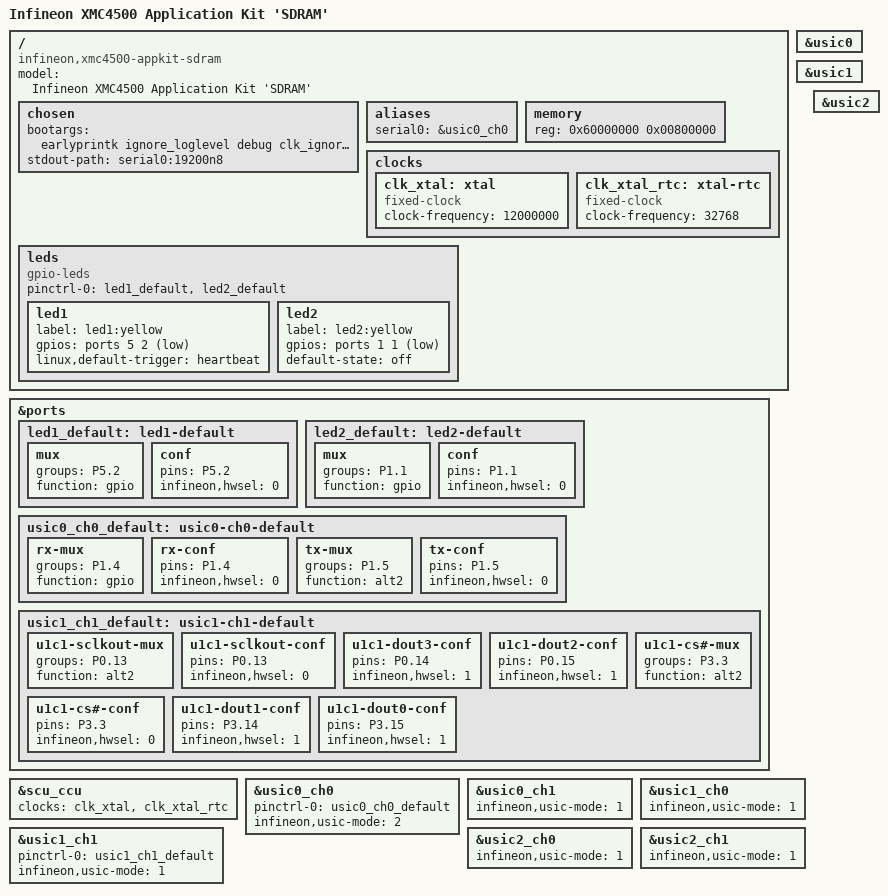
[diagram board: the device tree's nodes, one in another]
/*
 * Copyright 2015-2016 Andreas Färber
 *
 * This file is dual-licensed: you can use it either under the terms
 * of the GPL or the X11 license, at your option. Note that this dual
 * licensing only applies to this file, and not this project as a
 * whole.
 *
 *  a) This file is free software; you can redistribute it and/or
 *     modify it under the terms of the GNU General Public License as
 *     published by the Free Software Foundation; either version 2 of the
 *     License, or (at your option) any later version.
 *
 *     This file is distributed in the hope that it will be useful,
 *     but WITHOUT ANY WARRANTY; without even the implied warranty of
 *     MERCHANTABILITY or FITNESS FOR A PARTICULAR PURPOSE.  See the
 *     GNU General Public License for more details.
 *
 * Or, alternatively,
 *
 *  b) Permission is hereby granted, free of charge, to any person
 *     obtaining a copy of this software and associated documentation
 *     files (the "Software"), to deal in the Software without
 *     restriction, including without limitation the rights to use,
 *     copy, modify, merge, publish, distribute, sublicense, and/or
 *     sell copies of the Software, and to permit persons to whom the
 *     Software is furnished to do so, subject to the following
 *     conditions:
 *
 *     The above copyright notice and this permission notice shall be
 *     included in all copies or substantial portions of the Software.
 *
 *     THE SOFTWARE IS PROVIDED "AS IS", WITHOUT WARRANTY OF ANY KIND,
 *     EXPRESS OR IMPLIED, INCLUDING BUT NOT LIMITED TO THE WARRANTIES
 *     OF MERCHANTABILITY, FITNESS FOR A PARTICULAR PURPOSE AND
 *     NONINFRINGEMENT. IN NO EVENT SHALL THE AUTHORS OR COPYRIGHT
 *     HOLDERS BE LIABLE FOR ANY CLAIM, DAMAGES OR OTHER LIABILITY,
 *     WHETHER IN AN ACTION OF CONTRACT, TORT OR OTHERWISE, ARISING
 *     FROM, OUT OF OR IN CONNECTION WITH THE SOFTWARE OR THE USE OR
 *     OTHER DEALINGS IN THE SOFTWARE.
 */

/dts-v1/;

#include "xmc4500.dtsi"
#include <dt-bindings/gpio/gpio.h>

/ {
	model = "Infineon XMC4500 Application Kit 'SDRAM'";
	compatible = "infineon,xmc4500-appkit-sdram", "infineon,xmc4500";

	chosen {
		bootargs = "earlyprintk ignore_loglevel debug clk_ignore_unused";
		stdout-path = "serial0:19200n8";
	};

	aliases {
		serial0 = &usic0_ch0;
	};

	memory {
		reg = <0x60000000 0x00800000>;
	};

	clocks {
		clk_xtal: xtal {
			compatible = "fixed-clock";
			clock-frequency = <12000000>;
			#clock-cells = <0>;
		};

		clk_xtal_rtc: xtal-rtc {
			compatible = "fixed-clock";
			clock-frequency = <32768>;
			#clock-cells = <0>;
		};
	};

	leds {
		compatible = "gpio-leds";
		pinctrl-names = "default";
		pinctrl-0 = <&led1_default>, <&led2_default>;

		led1 {
			label = "led1:yellow";
			gpios = <&ports 5 2 GPIO_ACTIVE_LOW>;
			linux,default-trigger = "heartbeat";
		};

		led2 {
			label = "led2:yellow";
			gpios = <&ports 1 1 GPIO_ACTIVE_LOW>;
			/*linux,default-trigger = "heartbeat";*/
			default-state = "off";
		};
	};
};

&ports {
	led1_default: led1-default {
		mux {
			groups = "P5.2";
			function = "gpio";
		};

		conf {
			pins = "P5.2";
			infineon,hwsel = <0>;
		};
	};

	led2_default: led2-default {
		mux {
			groups = "P1.1";
			function = "gpio";
		};

		conf {
			pins = "P1.1";
			infineon,hwsel = <0>;
		};
	};

	usic0_ch0_default: usic0-ch0-default {
		rx-mux {
			groups = "P1.4";
			function = "gpio"; /* U0C0.DX0B */
		};

		rx-conf {
			pins = "P1.4";
			infineon,hwsel = <0>;
		};

		tx-mux {
			groups = "P1.5";
			function = "alt2"; /* U0C0.DOUT0 */
		};

		tx-conf {
			pins = "P1.5";
			infineon,hwsel = <0>;
		};
	};

	usic1_ch1_default: usic1-ch1-default {
		u1c1-sclkout-mux {
			groups = "P0.13";
			function = "alt2"; /* U1C1.SCLKOUT */
		};

		u1c1-sclkout-conf {
			pins = "P0.13";
			infineon,hwsel = <0>;
		};

		u1c1-dout3-conf {
			pins = "P0.14";
			infineon,hwsel = <1>; /* U1C1.DOUT3 */
		};

		u1c1-dout2-conf {
			pins = "P0.15";
			infineon,hwsel = <1>; /* U1C1.DOUT2 */
		};

		u1c1-cs#-mux {
			groups = "P3.3";
			function = "alt2"; /* U1C1.SELO1 */
		};

		u1c1-cs#-conf {
			pins = "P3.3";
			infineon,hwsel = <0>;
		};

		u1c1-dout1-conf {
			pins = "P3.14";
			infineon,hwsel = <1>; /* U1C1.DOUT1 */
		};

		u1c1-dout0-conf {
			pins = "P3.15";
			infineon,hwsel = <1>; /* U1C1.DOUT0 */
		};
	};
};

&scu_ccu {
	clocks = <&clk_xtal>, <&clk_xtal_rtc>;
	clock-names = "xtal", "xtal_rtc";
};

&usic0 {
	status = "okay";
};

&usic0_ch0 {
	status = "okay";
	pinctrl-names = "default";
	pinctrl-0 = <&usic0_ch0_default>;
	infineon,usic-mode = <2>;
};

&usic0_ch1 {
	status = "okay";
	infineon,usic-mode = <1>;
};

&usic1 {
	status = "okay";
};

&usic1_ch0 {
	status = "okay";
	infineon,usic-mode = <1>;
};

&usic1_ch1 {
	status = "okay";
	pinctrl-names = "default";
	pinctrl-0 = <&usic1_ch1_default>;
	infineon,usic-mode = <1>;
};

&usic2 {
	status = "okay";
};

&usic2_ch0 {
	status = "okay";
	infineon,usic-mode = <1>;
};

&usic2_ch1 {
	status = "okay";
	infineon,usic-mode = <1>;
};
